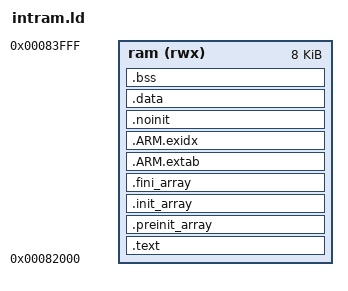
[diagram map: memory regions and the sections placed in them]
ENTRY(__enter_reset)

MEMORY
{
	ram (rwx) : ORIGIN = 0x00082000, LENGTH = 8k
}

SECTIONS
{
 .text : {
  *(.vectors)
  *(.text*)
  . = ALIGN(4);
  *(.rodata*)
  . = ALIGN(4);
 } >ram
 .preinit_array : {
  . = ALIGN(4);
  __preinit_array_start = .;
  KEEP (*(.preinit_array))
  __preinit_array_end = .;
 } >ram
 .init_array : {
  . = ALIGN(4);
  __init_array_start = .;
  KEEP (*(SORT(.init_array.*)))
  KEEP (*(.init_array))
  __init_array_end = .;
 } >ram
 .fini_array : {
  . = ALIGN(4);
  __fini_array_start = .;
  KEEP (*(.fini_array))
  KEEP (*(SORT(.fini_array.*)))
  __fini_array_end = .;
 } >ram
 .ARM.extab : {
  *(.ARM.extab*)
 } >ram
 .ARM.exidx : {
  __exidx_start = .;
  *(.ARM.exidx*)
  __exidx_end = .;
 } >ram
 . = ALIGN(4);
 _etext = .;
 .noinit (NOLOAD) : {
  *(.noinit*)
 } >ram
 . = ALIGN(4);
 .data : {
  _data = .;
  *(.data*)
  *(.ramtext*)
  . = ALIGN(4);
  _edata = .;
 } >ram AT >ram
 _data_loadaddr = LOADADDR(.data);
 .bss : {
  *(.bss*)
  *(COMMON)
  . = ALIGN(4);
  _ebss = .;
 } >ram
 /DISCARD/ : { *(.eh_frame) }
 . = ALIGN(4);
 end = .;
}
